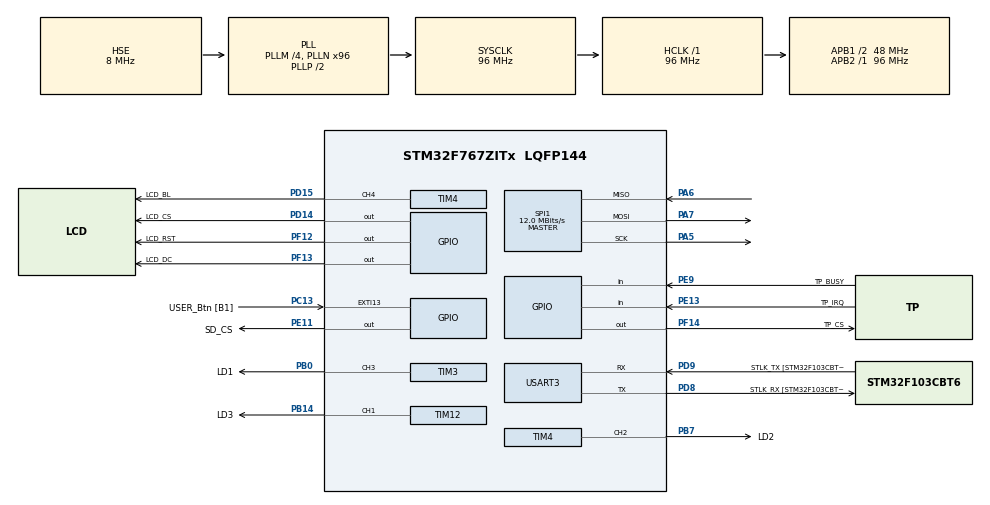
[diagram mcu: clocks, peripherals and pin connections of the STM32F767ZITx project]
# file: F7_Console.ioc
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Mcu.Family=STM32F7
Mcu.Name=STM32F767ZITx
Mcu.Package=LQFP144
NVIC.EXTI15_10_IRQn=true\:0\:0\:false\:false\:true\:true\:true\:true
NVIC.PriorityGroup=NVIC_PRIORITYGROUP_4
NVIC.TIM6_DAC_IRQn=true\:15\:0\:false\:false\:true\:false\:true\:true
NVIC.TIM7_IRQn=true\:0\:0\:false\:false\:true\:true\:true\:true
NVIC.TimeBase=TIM6_DAC_IRQn
NVIC.TimeBaseIP=TIM6
NVIC.USART3_IRQn=true\:0\:0\:false\:false\:true\:true\:true\:true
PA13.GPIO_Label=TMS
PA13.Mode=Serial_Wire
PA13.Signal=SYS_JTMS-SWDIO
PA14.GPIO_Label=TCK
PA14.Mode=Serial_Wire
PA14.Signal=SYS_JTCK-SWCLK
PA5.Mode=Full_Duplex_Master
PA5.Signal=SPI1_SCK
PA6.Mode=Full_Duplex_Master
PA6.Signal=SPI1_MISO
PA7.Mode=Full_Duplex_Master
PA7.Signal=SPI1_MOSI
PB0.GPIO_Label=LD1
PB0.Signal=S_TIM3_CH3
PB14.GPIO_Label=LD3
PB14.Signal=S_TIM12_CH1
PB7.GPIO_Label=LD2
PB7.Signal=S_TIM4_CH2
PC13.GPIO_Label=USER_Btn [B1]
PC13.GPIO_ModeDefaultEXTI=GPIO_MODE_IT_RISING
PC13.Signal=GPXTI13
PC14/OSC32_IN.Mode=LSE-External-Oscillator
PC14/OSC32_IN.Signal=RCC_OSC32_IN
PC15/OSC32_OUT.Mode=LSE-External-Oscillator
PC15/OSC32_OUT.Signal=RCC_OSC32_OUT
PD14.GPIO_Label=LCD_CS
PD14.PinState=GPIO_PIN_SET
PD14.Signal=GPIO_Output
PD15.GPIO_Label=LCD_BL
PD15.Signal=S_TIM4_CH4
PD8.GPIO_Label=STLK_RX [STM32F103CBT6_PA3]
PD8.Mode=Asynchronous
PD8.Signal=USART3_TX
PD9.GPIO_Label=STLK_TX [STM32F103CBT6_PA2]
PD9.Mode=Asynchronous
PD9.Signal=USART3_RX
PE11.GPIO_Label=SD_CS
PE11.PinState=GPIO_PIN_SET
PE11.Signal=GPIO_Output
PE13.GPIO_Label=TP_IRQ
PE13.Signal=GPIO_Input
PE9.GPIO_Label=TP_BUSY
PE9.Signal=GPIO_Input
PF12.GPIO_Label=LCD_RST
PF12.Signal=GPIO_Output
PF13.GPIO_Label=LCD_DC
PF13.Signal=GPIO_Output
PF14.GPIO_Label=TP_CS
PF14.PinState=GPIO_PIN_SET
PF14.Signal=GPIO_Output
PH0/OSC_IN.GPIO_Label=MCO [STM32F103CBT6_PA8]
PH0/OSC_IN.Mode=HSE-External-Clock-Source
PH0/OSC_IN.Signal=RCC_OSC_IN
PH1/OSC_OUT.Mode=HSE-External-Clock-Source
PH1/OSC_OUT.Signal=RCC_OSC_OUT
ProjectManager.HeapSize=0x400
ProjectManager.StackSize=0x800
ProjectManager.TargetToolchain=STM32CubeIDE
RCC.48MHZClocksFreq_Value=24000000
RCC.AHBFreq_Value=96000000
RCC.APB1CLKDivider=RCC_HCLK_DIV2
RCC.APB1Freq_Value=48000000
RCC.APB1TimFreq_Value=96000000
RCC.APB2Freq_Value=96000000
RCC.APB2TimFreq_Value=96000000
RCC.CortexFreq_Value=96000000
RCC.HCLKFreq_Value=96000000
RCC.HSE_VALUE=8000000
RCC.HSI_VALUE=16000000
RCC.PLLM=4
RCC.PLLMUL=RCC_PLL_MUL9
RCC.PLLN=96
RCC.PLLQ=4
RCC.PLLSourceVirtual=RCC_PLLSOURCE_HSE
RCC.PRESCALERUSB=RCC_USBCLKSOURCE_PLL_DIV1_5
RCC.SYSCLKFreq_VALUE=96000000
RCC.SYSCLKSource=RCC_SYSCLKSOURCE_PLLCLK
RCC.SYSCLKSourceVirtual=RCC_SYSCLKSOURCE_PLLCLK
RCC.USBFreq_Value=48000000
RCC.VCOOutputFreq_Value=192000000
SH.S_TIM12_CH1.0=TIM12_CH1,PWM Generation1 CH1
SH.S_TIM3_CH3.0=TIM3_CH3,PWM Generation3 CH3
SH.S_TIM4_CH2.0=TIM4_CH2,PWM Generation2 CH2
SH.S_TIM4_CH4.0=TIM4_CH4,PWM Generation4 CH4
SPI1.BaudRatePrescaler=SPI_BAUDRATEPRESCALER_8
SPI1.CalculateBaudRate=12.0 MBits/s
SPI1.DataSize=SPI_DATASIZE_8BIT
SPI1.Direction=SPI_DIRECTION_2LINES
SPI1.Mode=SPI_MODE_MASTER
SPI1.VirtualType=VM_MASTER
TIM12.Channel-PWM\ Generation1\ CH1=TIM_CHANNEL_1
TIM12.Period=1000 - 1
TIM12.Prescaler=960 - 1
TIM3.Channel-PWM\ Generation3\ CH3=TIM_CHANNEL_3
TIM3.Period=1000 - 1
TIM3.Prescaler=960 - 1
TIM4.Channel-PWM\ Generation2\ CH2=TIM_CHANNEL_2
TIM4.Channel-PWM\ Generation4\ CH4=TIM_CHANNEL_4
TIM4.Period=1000 - 1
TIM4.Prescaler=960 - 1
TIM7.Period=1000
TIM7.Prescaler=96 - 1
USART3.VirtualMode-Asynchronous=VM_ASYNC
VP_SYS_VS_tim6.Mode=TIM6
VP_TIM7_VS_ClockSourceINT.Mode=Enable_Timer
board=NUCLEO-F767ZI

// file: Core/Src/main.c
/* USER CODE BEGIN Header */
/**
  ******************************************************************************
  * @file           : main.c
  * @brief          : Main program body
  ******************************************************************************
  * @attention
  *
  * Copyright (c) 2023 STMicroelectronics.
  * All rights reserved.
  *
  * This software is licensed under terms that can be found in the LICENSE file
  * in the root directory of this software component.
  * If no LICENSE file comes with this software, it is provided AS-IS.
  *
  ******************************************************************************
  */
/* USER CODE END Header */
#include "main.h"
#include "spi.h"
#include "tim.h"
#include "usart.h"
#include "gpio.h"

/* USER CODE BEGIN Includes */
#include "mars_app.h"

/* USER CODE END Includes */

void SystemClock_Config(void);

int main(void)
{

  /* MCU Configuration--------------------------------------------------------*/

  /* Reset of all peripherals, Initializes the Flash interface and the Systick. */
  HAL_Init();

  /* Configure the system clock */
  SystemClock_Config();

  /* Initialize all configured peripherals */
  MX_GPIO_Init();
  MX_USART3_UART_Init();
  MX_TIM4_Init();
  MX_SPI1_Init();
  MX_TIM7_Init();
  MX_TIM3_Init();
  MX_TIM12_Init();
  /* USER CODE BEGIN 2 */
    mars_app_init();

  /* USER CODE END 2 */

  /* Infinite loop */
  /* USER CODE BEGIN WHILE */
  while (1)
  {
      mars_app_run();
    /* USER CODE END WHILE */

  }
}

void SystemClock_Config(void)
{
  RCC_OscInitTypeDef RCC_OscInitStruct = {0};
  RCC_ClkInitTypeDef RCC_ClkInitStruct = {0};

  /** Configure LSE Drive Capability
  */
  HAL_PWR_EnableBkUpAccess();

  /** Configure the main internal regulator output voltage
  */
  __HAL_RCC_PWR_CLK_ENABLE();
  __HAL_PWR_VOLTAGESCALING_CONFIG(PWR_REGULATOR_VOLTAGE_SCALE3);

  /** Initializes the RCC Oscillators according to the specified parameters
  * in the RCC_OscInitTypeDef structure.
  */
  RCC_OscInitStruct.OscillatorType = RCC_OSCILLATORTYPE_HSE;
  RCC_OscInitStruct.HSEState = RCC_HSE_BYPASS;
  RCC_OscInitStruct.PLL.PLLState = RCC_PLL_ON;
  RCC_OscInitStruct.PLL.PLLSource = RCC_PLLSOURCE_HSE;
  RCC_OscInitStruct.PLL.PLLM = 4;
  RCC_OscInitStruct.PLL.PLLN = 96;
  RCC_OscInitStruct.PLL.PLLP = RCC_PLLP_DIV2;
  RCC_OscInitStruct.PLL.PLLQ = 4;
  RCC_OscInitStruct.PLL.PLLR = 2;
  if (HAL_RCC_OscConfig(&RCC_OscInitStruct) != HAL_OK)
  {
    Error_Handler();
  }

  /** Activate the Over-Drive mode
  */
  if (HAL_PWREx_EnableOverDrive() != HAL_OK)
  {
    Error_Handler();
  }

  /** Initializes the CPU, AHB and APB buses clocks
  */
  RCC_ClkInitStruct.ClockType = RCC_CLOCKTYPE_HCLK|RCC_CLOCKTYPE_SYSCLK
                              |RCC_CLOCKTYPE_PCLK1|RCC_CLOCKTYPE_PCLK2;
  RCC_ClkInitStruct.SYSCLKSource = RCC_SYSCLKSOURCE_PLLCLK;
  RCC_ClkInitStruct.AHBCLKDivider = RCC_SYSCLK_DIV1;
  RCC_ClkInitStruct.APB1CLKDivider = RCC_HCLK_DIV2;
  RCC_ClkInitStruct.APB2CLKDivider = RCC_HCLK_DIV1;

  if (HAL_RCC_ClockConfig(&RCC_ClkInitStruct, FLASH_LATENCY_3) != HAL_OK)
  {
    Error_Handler();
  }
}

void HAL_TIM_PeriodElapsedCallback(TIM_HandleTypeDef *htim)
{
  if (htim->Instance == TIM6) {
    HAL_IncTick();
  }
  /* USER CODE BEGIN Callback 1 */
    if (htim->Instance == TIM7) {
        time_run();
    }

  /* USER CODE END Callback 1 */
}

void Error_Handler(void)
{
  __disable_irq();
  while (1)
  {
  }
}
